CM_ "IMPORT _honda_common.dbc";
CM_ "IMPORT _bosch_2023_odyssey.dbc";
CM_ "IMPORT _steering_control_a.dbc";
CM_ "IMPORT _steering_sensors_b.dbc";
CM_ "IMPORT _gearbox_common.dbc";
CM_ "IMPORT _nidec_scm_group_a.dbc";
CM_ "IMPORT _lkas_hud_8byte.dbc";
CM_ "IMPORT _bosch_standstill.dbc";
CM_ "IMPORT _bosch_radarless_common.dbc";

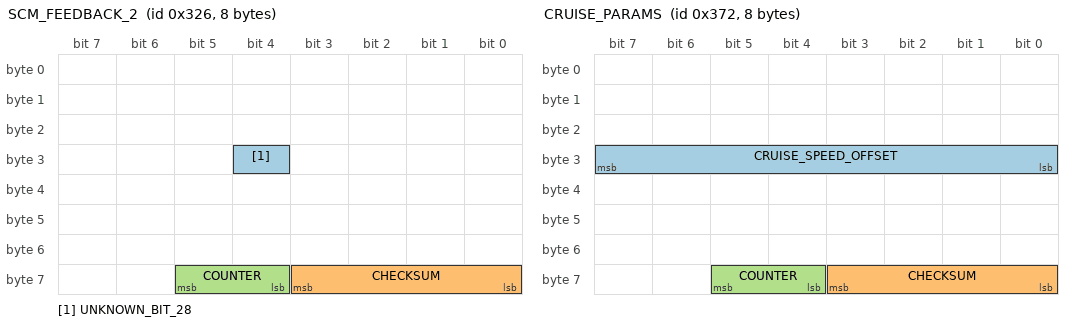
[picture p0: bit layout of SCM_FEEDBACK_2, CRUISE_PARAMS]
BO_ 806 SCM_FEEDBACK_2: 8 SCM
 SG_ UNKNOWN_BIT_28 : 28|1@0+ (1,0) [0|1] "" EON
 SG_ CHECKSUM : 59|4@0+ (1,0) [0|15] "" EON
 SG_ COUNTER : 61|2@0+ (1,0) [0|3] "" EON

BO_ 882 CRUISE_PARAMS: 8 PCM
 SG_ CRUISE_SPEED_OFFSET : 31|8@0- (0.1,0) [-128|127] "kph" EON
 SG_ CHECKSUM : 59|4@0+ (1,0) [0|3] "" EON
 SG_ COUNTER : 61|2@0+ (1,0) [0|15] "" EON

CM_ BO_ 806 "Unknown on this car, defined only because the safety RX checks it (0x326 is SCM_FEEDBACK on Bosch)";
CM_ SG_ 806 UNKNOWN_BIT_28 "Not verified on this car. Declared because the safety reads it as MAIN_ON until SCM_BUTTONS (0x1A6) is seen";
